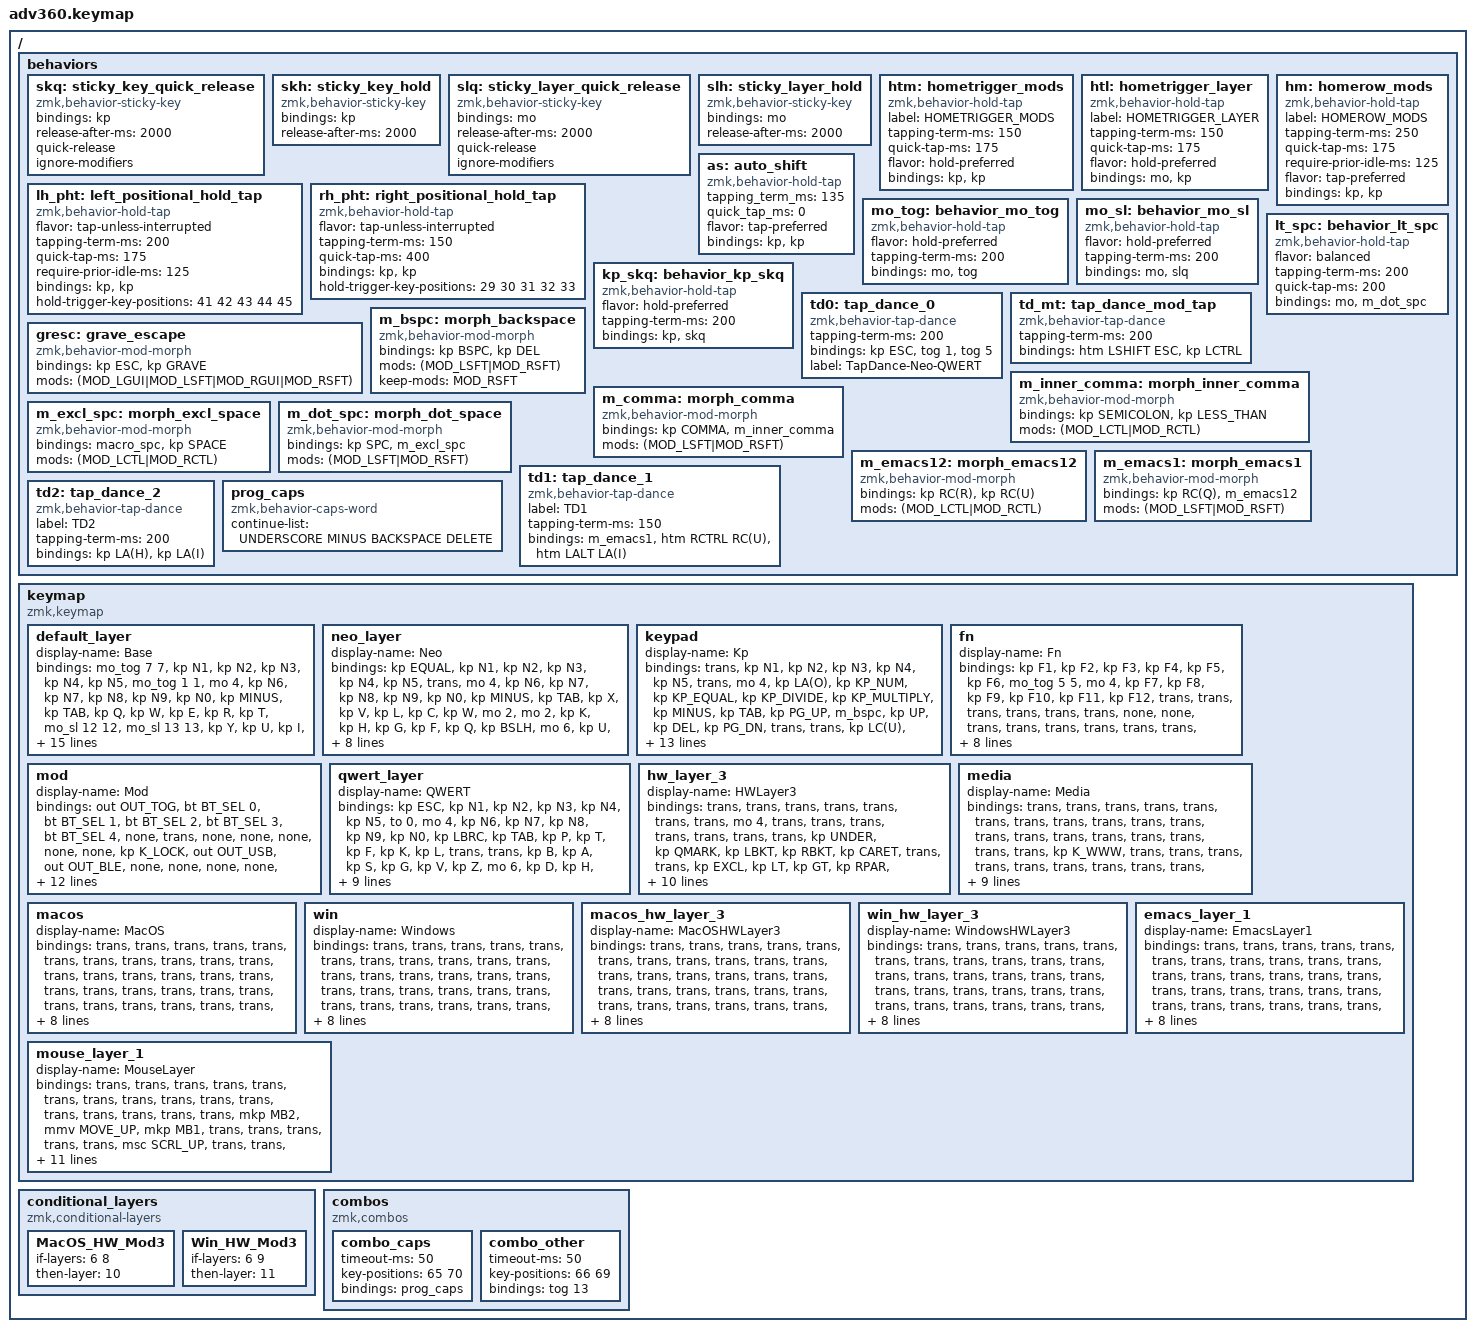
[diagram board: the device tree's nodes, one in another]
/*
 * Copyright 2025 Jonathan Pieper <jpieper@mailbox.org>
 *
 * This program is free software: you can redistribute it and/or modify
 * it under the terms of the GNU General Public License as published by
 * the Free Software Foundation, either version 3 of the License, or
 * (at your option) any later version.
 *
 * This program is distributed in the hope that it will be useful,
 * but WITHOUT ANY WARRANTY; without even the implied warranty of
 * MERCHANTABILITY or FITNESS FOR A PARTICULAR PURPOSE. See the
 * GNU General Public License for more details.
 *
 * You should have received a copy of the GNU General Public License
 * along with this program. If not, see <http://www.gnu.org/licenses/>.
 */

/*
 *
 * Neo2 layout for Kinesis Advantage 360 Pro
 *
 * The general idea is to have three layers that can be toggled:
 *
 * – standard Neo2
 * – poor man’s Neo2 ((partial) Neo2 with QWERTZ active on the host system)
 * – poor man’s QWERTZ ((partial) QWERTZ with Neo2 active on the host system)
 *
 * Inspired by:
 * - https://github.com/kaimi/tmk_keyboard/blob/neo2/keyboard/ergodox/keymap_neo.c
 * - https://github.com/urob/zmk-config/blob/main/config/base.keymap
 * - https://github.com/marlonrichert/raise-ergo
 * - https://github.com/kucera-lukas/zmk-config
 */

#include <dt-bindings/zmk/stp.h>
#include <behaviors.dtsi>
#include <dt-bindings/zmk/backlight.h>
#include <dt-bindings/zmk/bt.h>
#include <dt-bindings/zmk/keys.h>
#include <dt-bindings/zmk/outputs.h>
#include <dt-bindings/zmk/pointing.h>
#include <dt-bindings/zmk/rgb.h>

/ {
    behaviors {
        #include "macros.dtsi"
        #include "version.dtsi"

        // Sticky Keys

        skq: sticky_key_quick_release {
            compatible = "zmk,behavior-sticky-key";
            #binding-cells = <1>;
            bindings = <&kp>;
            release-after-ms = <2000>;
            quick-release;
            ignore-modifiers;
        };

        skh: sticky_key_hold {
            compatible = "zmk,behavior-sticky-key";
            #binding-cells = <1>;
            bindings = <&kp>;
            release-after-ms = <2000>;

            /delete-property/ ignore-modifiers;
        };

        //
        // Sticky Layers

        slq: sticky_layer_quick_release {
            compatible = "zmk,behavior-sticky-key";
            #binding-cells = <1>;
            bindings = <&mo>;
            release-after-ms = <2000>;
            quick-release;
            ignore-modifiers;
        };

        slh: sticky_layer_hold {
            compatible = "zmk,behavior-sticky-key";
            #binding-cells = <1>;
            bindings = <&mo>;
            release-after-ms = <2000>;

            /delete-property/ ignore-modifiers;
        };

        /*
         * Hometrigger Mods (hm): hold-preferred
         *
         * Hold (kp <1>)
         * Tap  (kp <2>)
         */

        htm: hometrigger_mods {
            compatible = "zmk,behavior-hold-tap";
            label = "HOMETRIGGER_MODS";
            #binding-cells = <2>;
            tapping-term-ms = <150>;
            quick-tap-ms = <175>;
            flavor = "hold-preferred";
            bindings = <&kp>, <&kp>;
        };

        // Hold (mo <1>)
        // Tap  (kp <2>)
        htl: hometrigger_layer {
            compatible = "zmk,behavior-hold-tap";
            label = "HOMETRIGGER_LAYER";
            #binding-cells = <2>;
            tapping-term-ms = <150>;
            quick-tap-ms = <175>;
            flavor = "hold-preferred";
            bindings = <&mo>, <&kp>;
        };


        /*
         * From https://zmk.dev/docs/keymaps/behaviors/hold-tap?examples=homerow_mods
         *
         * Homerow Mods (hm): tap-preferred
         *
         * Hold (kp <1>)
         * Tap  (kp <2>)
         */

        hm: homerow_mods {
            compatible = "zmk,behavior-hold-tap";
            label = "HOMEROW_MODS";
            #binding-cells = <2>;
            tapping-term-ms = <250>;
            quick-tap-ms = <175>;
            require-prior-idle-ms = <125>;
            flavor = "tap-preferred";
            bindings = <&kp>, <&kp>;
        };

        /*
         * cross-hand only modifiers, using tap-unless-interrupted and positional hold-tap (hold-trigger-key-positions)
         */

        lh_pht: left_positional_hold_tap {
            compatible = "zmk,behavior-hold-tap";
            #binding-cells = <2>;
            flavor = "tap-unless-interrupted";
            tapping-term-ms = <200>;   // how long a key must be pressed to trigger the "hold" behavior
            quick-tap-ms = <175>;      // press key again within quick-tap-ms to tap
            require-prior-idle-ms = <125>;
            bindings = <&kp>, <&kp>;

            // press any key not listed in hold-trigger-key-positions
            // before tapping-term-ms expires, it will produce a tap

            hold-trigger-key-positions = <41 42 43 44 45>;
        };

        rh_pht: right_positional_hold_tap {
            compatible = "zmk,behavior-hold-tap";
            #binding-cells = <2>;
            flavor = "tap-unless-interrupted";
            tapping-term-ms = <150>;
            quick-tap-ms = <400>;
            bindings = <&kp>, <&kp>;

            hold-trigger-key-positions = <29 30 31 32 33>;
        };

        /*
         * From https://zmk.dev/docs/keymaps/behaviors/hold-tap?examples=autoshift
         *
         * A popular method of implementing Autoshift in ZMK involves a C-preprocessor macro, commonly defined as AS(keycode).
         * This macro applies the LSHIFT modifier to the specified keycode when AS(keycode) is held,
         * and simply performs a keypress, &kp keycode, when the AS(keycode) binding is tapped.
         * This simplifies the use of Autoshift in a keymap, as the complete hold-tap bindings for each desired Autoshift key,
         * as in &as LS(<keycode 1>) <keycode 1> &as LS(<keycode 2>) <keycode 2> ... &as LS(<keycode n>) <keycode n>,
         * can be quite cumbersome to use when applied to a large portion of the keymap.
         *
         * See macro above:
         * #define AS(keycode) &as LS(keycode) keycode     // Autoshift Macro
         *
         * Example:
         * AS(Q) AS(W) AS(E) AS(R) AS(T) AS(Y)
         */

        as: auto_shift {
            compatible = "zmk,behavior-hold-tap";
            #binding-cells = <2>;
            tapping_term_ms = <135>;
            quick_tap_ms = <0>;
            flavor = "tap-preferred";
            bindings = <&kp>, <&kp>;
        };

        /*
         * From https://zmk.dev/docs/keymaps/behaviors/hold-tap?examples=mo_tog
         *
         * This hold-tap example implements a momentary-layer when the keybind is held and a toggle-layer when it is tapped.
         * Similar to the Autoshift and Sticky Hold use-cases, a MO_TOG(layer)
         * macro is defined such that the &mo and &tog behaviors can target a single layer.
         *
         * Hold
         *   Momentary (mo <1>)
         * Tap
         *   Toggle (tog <2>)
         */

        mo_tog: behavior_mo_tog {
            compatible = "zmk,behavior-hold-tap";
            #binding-cells = <2>;
            flavor = "hold-preferred";
            tapping-term-ms = <200>;
            bindings = <&mo>, <&tog>;
        };

        /*
         * mo_sl: Momentary Layer or Sticky Layer
         *
         * Hold
         *   Momentary (mo <1>)
         * Tap
         *   Sticky Layer (slq <2>)
         */

        mo_sl: behavior_mo_sl {
            compatible = "zmk,behavior-hold-tap";
            #binding-cells = <2>;
            flavor = "hold-preferred";
            tapping-term-ms = <200>;
            bindings = <&mo>, <&slq>;
        };

        kp_skq: behavior_kp_skq {
            compatible = "zmk,behavior-hold-tap";
            #binding-cells = <2>;
            flavor = "hold-preferred";
            tapping-term-ms = <200>;
            bindings = <&kp>, <&skq>;
        };

        // lt_spc: Momentary Layer or Space Sticky Shift Macro
        // Tap: space
        // s-   tap: dot -> space -> sticky shift
        // C-s- tap: excl(!) -> space -> sticky shift
        // Hold: Momentary new layer (mo <1>).

        lt_spc: behavior_lt_spc {
            compatible = "zmk,behavior-hold-tap";
            #binding-cells = <2>;
            flavor = "balanced";
            tapping-term-ms = <200>;
            quick-tap-ms = <200>;
            bindings = <&mo>, <&m_dot_spc>;
        };

        // Tap Dance: tap multiple times for different outcomes
        /*
         * Tap Dance 0 (td0):
         *
         * Tap 1 (kp ESC)
         * Tap 2 (mo 1) (Neo)
         * Tap 3 (mo 5) (QWERTY)
         */

        td0: tap_dance_0 {
            compatible = "zmk,behavior-tap-dance";
            #binding-cells = <0>;
            tapping-term-ms = <200>;
            bindings = <&kp ESC>, <&tog 1>, <&tog 5>;

            label = "TapDance-Neo-QWERT";
        };

        // Mod Tap (td_mt):
        //
        // Tap 1: ESC
        // Tap 2: LCTRL
        // Hold: LSHIFT

        td_mt: tap_dance_mod_tap {
            compatible = "zmk,behavior-tap-dance";
            #binding-cells = <0>;
            tapping-term-ms = <200>;
            bindings = <&htm LSHIFT ESC>, <&kp LCTRL>;
        };

        // mod-morph (Morphing Keys)
        //
        // From https://zmk.dev/docs/keymaps/behaviors/mod-morph

        gresc: grave_escape {
            compatible = "zmk,behavior-mod-morph";
            #binding-cells = <0>;
            bindings = <&kp ESC>, <&kp GRAVE>;

            mods = <(MOD_LGUI|MOD_LSFT|MOD_RGUI|MOD_RSFT)>;
        };

        // From https://github.com/urob/zmk-config/blob/main/config/base.keymap
        // Tap: backspace
        // Lshft + tap: delete
        // Rshft + tap: shift-delete.

        m_bspc: morph_backspace {
            compatible = "zmk,behavior-mod-morph";
            #binding-cells = <0>;
            bindings = <&kp BSPC>, <&kp DEL>;

            mods = <(MOD_LSFT|MOD_RSFT)>;
            keep-mods = <MOD_RSFT>;
        };

        // Tap: comma
        // Shift + tap: semicolon
        // Ctrl + shift + tap: <

        m_inner_comma: morph_inner_comma {
            compatible = "zmk,behavior-mod-morph";
            #binding-cells = <0>;
            bindings = <&kp SEMICOLON>, <&kp LESS_THAN>;

            mods = <(MOD_LCTL|MOD_RCTL)>;
        };

        m_comma: morph_comma {
            compatible = "zmk,behavior-mod-morph";
            #binding-cells = <0>;
            bindings = <&kp COMMA>, <&m_inner_comma>;

            mods = <(MOD_LSFT|MOD_RSFT)>;
        };

        // Tap: Space
        // Shift tap: dot              -> space -> sticky shift
        // C-sft-tap: Space

        m_excl_spc: morph_excl_space {
            compatible = "zmk,behavior-mod-morph";
            #binding-cells = <0>;
            bindings = <&macro_spc>, <&kp SPACE>;

            mods = <(MOD_LCTL|MOD_RCTL)>;
        };

        m_dot_spc: morph_dot_space {
            compatible = "zmk,behavior-mod-morph";
            #binding-cells = <0>;
            bindings = <&kp SPC>, <&m_excl_spc>;

            mods = <(MOD_LSFT|MOD_RSFT)>;
        };

        m_emacs12: morph_emacs12 {
            compatible = "zmk,behavior-mod-morph";
            #binding-cells = <0>;
            bindings = <&kp RC(R)>,    // C-c
	               <&kp RC(U)>;    // C-h

            mods = <(MOD_LCTL|MOD_RCTL)>;
        };

        m_emacs1: morph_emacs1 {
            compatible = "zmk,behavior-mod-morph";
            #binding-cells = <0>;
            bindings = <&kp RC(Q)>,    // C-x
	               <&m_emacs12>;

            mods = <(MOD_LSFT|MOD_RSFT)>;
        };

        td1: tap_dance_1 {
            compatible = "zmk,behavior-tap-dance";
            label = "TD1";
            #binding-cells = <0>;
            tapping-term-ms = <150>;
            bindings =
                <&m_emacs1>, // Hold:  RGUI   Tap: C-x
                <&htm RCTRL RC(U)>, // Hold: RCTL   Tap: C-h
                <&htm LALT LA(I)>; // Hold:  LALT   Tap: M-g
        };

        td2: tap_dance_2 {
            compatible = "zmk,behavior-tap-dance";
            label = "TD2";
            #binding-cells = <0>;
            tapping-term-ms = <200>;
            bindings =
                <&kp LA(H)>, // M-s
                <&kp LA(I)>; // M-g
        };

    	prog_caps: prog_caps {
            compatible = "zmk,behavior-caps-word";
            #binding-cells = <0>;
            continue-list = <UNDERSCORE MINUS BACKSPACE DELETE>;
        };

    };

    keymap {
        compatible = "zmk,keymap";

        /* Keymap 0:
     *
     * Default Layer (Neo2, original QWERTY)
     *
     * This is mostly just the standard Layout with some modifications.
     *
     * ,--------------------------------------------------.           ,--------------------------------------------------.
     * |  Esc   |   1  |   2  |   3  |   4  |   5  |Neo/Md|           | To 4 |   6  |   7  |   8  |   9  |   0  |   -    |
     * |--------+------+------+------+------+-------------|           |------+------+------+------+------+------+--------|
     * |  Tab   |   X  |   V  |   L  |   C  |   W  | C-c  |           | C-x  |   K  |   H  |   G  |   F  |   Q  |   ß  \ |
     * |--------+------+------+------+------+------|------|           |------|------+------+------+------+------+--------|
     * |  M-w   |   U  |   I  |   A  |   E  |   O  | M-s  |           | M-x  |   S  |   N  |   R  |   T  |   D  |   Y    |
     * |  CAPS  | LGUI | LSHFT| LALT | LCTRL|      |      |           |      |      | RCTRL| RALT | RSHFT| RGUI | CAPS   | <-- Homerow Mods
     * |--------+------+------+------+------+------|------'           `------|------+------+------+------+------+--------|
     * |  LSft  |   Ü  |   Ö  |   Ä  |   P  |   Z  |                         |   B  |   M  |   ,  |   .  |   J  |  RSft  |
     * |--------+------+------+------+------+------'                         `------+------+------+------+------+--------|
     * |  Fn    | ESC  | Kp   | LEFT | RIGHT|                                       |  UP  | DOWN |   [  |   ]  | Fn     |
     * `------------------------------------'                                       `------------------------------------'
     *                                        ,-------------.       ,-------------.
     *                                        | CTRL | ALT  |       | LGUI | CTRL |
     *                                 ,------|------|------|       |------+------+------.
     *                                 |      |      | Mod3 |       | Mod3 |      |      |
     *                                 | SHIFT| SPC  |------|       |------| RET  | SHIFT|
     *                                 |      |      | Mod4 |       | Mod4 |      |      |
     *                                 `--------------------'       `--------------------'
     */

        default_layer {
            display-name = "Base";
            bindings = <
&mo_tog 7 7      &kp N1          &kp N2            &kp N3          &kp N4           &kp N5          &mo_tog 1 1                                                          &mo 4                 &kp N6          &kp N7           &kp N8          &kp N9            &kp N0             &kp MINUS
&kp TAB          &kp Q           &kp W             &kp E           &kp R            &kp T           &mo_sl 12 12                                                         &mo_sl 13 13          &kp Y           &kp U            &kp I           &kp O             &kp P              &kp LBKT
&kp CAPS         &hm LGUI A    &hm LALT S        &hm LSHFT D     &hm LCTRL F      &hm RALT G      &htm CAPS LC(H)   &kp LCTRL     &kp LALT      &kp LGUI       &kp RCTRL  &htm CAPS LA(Q)    &hm RALT H      &hm RCTRL J      &hm RSHIFT K    &hm LALT L        &hm RGUI SEMI      &hm CAPS SQT
&kp LSHFT  &kp Z       &kp X             &kp C           &kp V            &kp B                                           &kp_skq CAPS CAPS  &kp_skq BSLH BSLH                       &kp N           &kp M            &m_comma        &kp DOT           &kp FSLH           &kp RSHFT
&mo_sl 2 3       &m_dot_spc      &mo_tog 2 2       &htm CAPS LEFT   &htm LGUI RIGHT                   &kp BSPC  &key_repeat   &mo_tog 2 2   &kp RIGHT_ALT  &kp ENTER  &kp SPACE            &htm CAPS UP     &htm RALT DOWN  &htm CAPS LBKT    &htm RALT RBKT     &mo_sl 12 3
            >;
        };

        /* Keymap 1:
     *
     * Hardware Neo2
     *
     * This is a hardware implementation of Neo2. Allowing to type in Neo2 even if it is not installed.
     *
     * ,--------------------------------------------------.           ,--------------------------------------------------.
     * |  Esc   |   1  |   2  |   3  |   4  |   5  | trans|           | To 4 |   6  |   7  |   8  |   9  |   0  |   -    |
     * |--------+------+------+------+------+-------------|           |------+------+------+------+------+------+--------|
     * |  Tab   |   X  |   V  |   L  |   C  |   W  | C-c  |           | C-x  |   K  |   H  |   G  |   F  |   Q  |   ß    |
     * |--------+------+------+------+------+------|------|           |------|------+------+------+------+------+--------|
     * | HMod3  |   U  |   I  |   A  |   E  |   O  | M-s  |           | M-x  |   S  |   N  |   R  |   T  |   D  |   Y    |
     * |--------+------+------+------+------+------|------'           `------|------+------+------+------+------+--------|
     * |  LSft  |  Ü [ |  Ö / |  Ä ; |   P  |   Z  |                         |   B  |   M  |   ,  |   .  |   J  |  RSft  |
     * |--------+------+------+------+------+------'                         `------+------+------+------+------+--------|
     * |  Fn    | ESC  | LGUI | LEFT | RIGHT|                                       |  UP  | DOWN |   [  |   ]  | Fn     |
     * `------------------------------------'                                       `------------------------------------'
     *                                        ,-------------.       ,-------------.
     *                                        | trans| trans|       | trans| trans|
     *                                 ,------|------|------|       |------+------+------.
     *                                 |      |      | trans|       | Mod3 |      |      |
     *                                 | trans| trans|------|       |------| trans| trans|
     *                                 |      |      | trans|       | Mod4 |      |      |
     *                                 `--------------------'       `--------------------'
     */

        neo_layer {
            display-name = "Neo";
            bindings = <
&kp EQUAL    &kp N1    &kp N2      &kp N3    &kp N4     &kp N5  &trans                                      &mo 4   &kp N6  &kp N7  &kp N8     &kp N9    &kp N0    &kp MINUS
&kp TAB      &kp X     &kp V       &kp L     &kp C      &kp W   &mo 2                                       &mo 2   &kp K   &kp H   &kp G      &kp F     &kp Q     &kp BSLH
&mo 6        &kp U     &kp I       &kp A     &kp E      &kp O   &mo 6   &trans  &trans      &trans  &trans  &mo 6   &kp S   &kp N   &kp R      &kp T     &kp D     &kp Z
&kp LSHFT    &kp LBKT  &kp SLASH   &kp SEMI  &kp P      &kp Y                   &mo 6       &mo 6                   &kp B   &kp M   &kp COMMA  &kp DOT   &kp J     &kp RSHFT
&mo_sl 2 3   &kp ESC   &mo_sl 2 2  &kp LEFT  &kp RIGHT          &trans  &trans  &mo 2       &mo 2   &trans  &trans          &kp UP  &kp DOWN   &kp LBKT  &kp RBKT  &trans
            >;
        };

        /* Keymap 2:
     *
     * Keypad (Kp, Mod4)
     *
     * This is a hardware implementation of the Neo2-Mod4 Keypad Layer.
     *
     * ,--------------------------------------------------.           ,--------------------------------------------------.
     * |  Esc   | trans| trans| trans| trans| trans| trans|           | To 4 | M-f  |  NUM |   =  |   /  |   *  |   -    |
     * |--------+------+------+------+------+-------------|           |------+------+------+------+------+------+--------|
     * |  Tab   | Pg_Up| BKSP |  UP  |  DEL | Pg_Dn| trans|           | trans| C-h  |   7  |   8  |   9  |   -  |   \    |
     * |--------+------+------+------+------+------|------|           |------|------+------+------+------+------+--------|
     * |  Mod3  | HOME | LEFT | DOWN | RIGHT| END  | trans|           | trans| M-s  |   4  |   5  |   6  |   +  |   '    |
     * |--------+------+------+------+------+------|------'           `------|------+------+------+------+------+--------|
     * |  LSft  | ESC  |  TAB | INS  | RET  | UNDO |                         |   :  |   1  |   2  |   3  |  RET |  RSft  |
     * |--------+------+------+------+------+------'                         `------+------+------+------+------+--------|
     * |  MacOST|HMod3 | trans| BriDn| BriUp|                                       | VolUp| VolDn| MUTE | PLAY | Fn     |
     * `------------------------------------'                                       `------------------------------------'
     *                                        ,-------------.       ,-------------.
     *                                        | trans| trans|       | trans| trans|
     *                                 ,------|------|------|       |------+------+------.
     *                                 |      |      | trans|       | trans|      |      |
     *                                 | trans| trans|------|       |------| DEL  |  0   |
     *                                 |      |      | trans|       | trans|      |      |
     *                                 `--------------------'       `--------------------'
     */

        keypad {
            display-name = "Kp";
            bindings = <
&trans       &kp N1     &kp N2    &kp N3        &kp N4        &kp N5      &trans                                       &mo 4         &kp LA(O)  &kp KP_NUM    &kp KP_EQUAL  &kp KP_DIVIDE  &kp KP_MULTIPLY   &kp MINUS
&kp TAB      &kp PG_UP  &m_bspc   &kp UP        &kp DEL       &kp PG_DN   &trans                                       &trans        &kp LC(U)  &kp KP_N7     &kp KP_N8     &kp KP_N9      &kp KP_MINUS      &kp BSLH
&kp CAPS     &kp HOME   &kp LEFT  &kp DOWN      &kp RIGHT     &kp END     &trans  &trans  &trans      &trans  &trans   &trans        &kp LA(H)  &kp KP_N4     &kp KP_N5     &kp KP_N6      &kp KP_PLUS       &kp SQT
&trans       &kp ESC    &kp TAB   &kp LG(V)     &kp RET       &kp K_UNDO                  &trans      &trans                         &kp COLON  &kp KP_N1     &kp KP_N2     &kp KP_N3      &kp KP_ENTER      &kp RSHFT
&mo_tog 7 5  &mo 6      &trans    &kp C_BRI_DN  &kp C_BRI_UP              &trans  &trans  &trans      &trans  &kp DEL  &kp NUMBER_0             &kp C_VOL_UP  &kp C_VOL_DN  &kp C_MUTE     &kp K_PLAY_PAUSE  &trans
            >;
        };

        /* Keymap 3:
     *
     * Function Keys (Fn)
     *
     * This is the function layer (Fn).
     *
     * ,--------------------------------------------------.           ,--------------------------------------------------.
     * |  F1    | F2   | F3   | F4   | F5   | F6   | QWERT|           | Mo 4 | F7   |  F8  |  F9  | F10  | F11  | F12    |
     * |--------+------+------+------+------+-------------|           |------+------+------+------+------+------+--------|
     * |  trans | trans| trans| trans| trans| trans| trans|           | trans| trans| trans| trans| trans| trans| trans  |
     * |--------+------+------+------+------+------|------|           |------|------+------+------+------+------+--------|
     * |  trans | trans| trans| trans| trans| trans| trans|           | trans| trans| trans| trans| trans| trans| trans  |
     * |--------+------+------+------+------+------|------'           `------|------+------+------+------+------+--------|
     * |  trans | trans| trans| trans| trans| trans|                         | trans| trans| trans| trans| trans| trans  |
     * |--------+------+------+------+------+------'                         `------+------+------+------+------+--------|
     * |  trans | trans| trans| trans| trans|                                       | trans| trans| trans| trans| trans  |
     * `------------------------------------'                                       `------------------------------------'
     *                                        ,-------------.       ,-------------.
     *                                        | trans| trans|       | trans| trans|
     *                                 ,------|------|------|       |------+------+------.
     *                                 |      |      | trans|       | trans|      |      |
     *                                 | trans| trans|------|       |------| trans| trans|
     *                                 |      |      | trans|       | trans|      |      |
     *                                 `--------------------'       `--------------------'
     */

        fn {
            display-name = "Fn";
            bindings = <
&kp F1  &kp F2  &kp F3  &kp F4  &kp F5  &kp F6  &mo_tog 5 5                                         &mo 4   &kp F7  &kp F8  &kp F9  &kp F10  &kp F11  &kp F12
&trans  &trans  &trans  &trans  &trans  &trans  &none                                               &none   &trans  &trans  &trans  &trans   &trans   &trans
&trans  &trans  &trans  &trans  &trans  &trans  &none        &trans  &trans      &kp K_APP  &trans  &none   &trans  &trans  &trans  &trans   &trans   &trans
&trans  &trans  &trans  &trans  &trans  &trans                       &trans      &trans                     &trans  &trans  &trans  &trans   &trans   &trans
&trans  &trans  &trans  &trans  &trans          &kp SPACE    &trans  &trans      &trans     &trans  &trans          &trans  &trans  &trans   &trans   &trans
            >;
        };

        /* Keymap 4:
     *
     * Keyboard Modification Layer (Mod)
     *
     * This is the Mod Layer.
     *
     * ,--------------------------------------------------.           ,--------------------------------------------------.
     * |  trans | trans| trans| trans| trans| trans| trans|           | trans| trans| trans| trans| trans| trans| trans  |
     * |--------+------+------+------+------+-------------|           |------+------+------+------+------+------+--------|
     * |  trans | trans| trans| trans| trans| trans| trans|           | trans| trans| trans| trans| trans| trans| trans  |
     * |--------+------+------+------+------+------|------|           |------|------+------+------+------+------+--------|
     * |  trans | trans| trans| trans| trans| trans| trans|           | trans| trans| trans| trans| trans| trans| trans  |
     * |--------+------+------+------+------+------|------'           `------|------+------+------+------+------+--------|
     * |  trans | trans| trans| trans| trans| trans|                         | trans| trans| trans| trans| trans| trans  |
     * |--------+------+------+------+------+------'                         `------+------+------+------+------+--------|
     * |  trans | trans| trans| trans| trans|                                       | trans| trans| trans| trans| trans  |
     * `------------------------------------'                                       `------------------------------------'
     *                                        ,-------------.       ,-------------.
     *                                        | trans| trans|       | trans| trans|
     *                                 ,------|------|------|       |------+------+------.
     *                                 |      |      | trans|       | trans|      |      |
     *                                 | trans| trans|------|       |------| trans| trans|
     *                                 |      |      | trans|       | trans|      |      |
     *                                 `--------------------'       `--------------------'
     */

        mod {
            display-name = "Mod";
            bindings = <
&out OUT_TOG    &bt BT_SEL 0  &bt BT_SEL 1  &bt BT_SEL 2  &bt BT_SEL 3  &bt BT_SEL 4  &none                                                                     &trans           &none  &none       &none       &none  &none  &kp K_LOCK
&out OUT_USB    &out OUT_BLE  &none         &none         &none         &none         &bootloader                                                               &bootloader      &none  &none       &none       &none  &none  &none
&studio_unlock  &none         &none         &none         &none         &none         &none            &bt BT_PRV       &bt BT_NXT      &bt BT_CLR  &none       &stp STP_BAT     &none  &none       &none       &none  &none  &none
&none           &none         &none         &none         &macro_ver    &none                                           &rgb_ug RGB_BRI  &rgb_ug RGB_HUI                         &none  &none       &none       &none  &none  &none
&none           &none         &none         &none         &none                       &soft_off        &rgb_ug RGB_TOG  &rgb_ug RGB_BRD  &rgb_ug RGB_HUI  &bl BL_TOG  &rgb_ug RGB_TOG   &bl BL_INC  &bl BL_DEC  &bl BL_CYCLE  &none  &none
            >;
        };

        /* Keymap 5:
     *
     * QWERTY Layer (QWERT)
     *
     * This is the poor mans QWERTY. Sometimes you need to enter in qwerty even if neo is active.
     *
     * ,--------------------------------------------------.           ,--------------------------------------------------.
     * |  Esc   |   1  |   2  |   3  |   4  |   5  | To 0 |           | To 4 |   6  |   7  |   8  |   9  |   0  |   -    |
     * |--------+------+------+------+------+-------------|           |------+------+------+------+------+------+--------|
     * |  Tab   |   Q  |   W  |   E  |   R  |   T  | trans|           | trans|   Z  |   U  |   I  |   O  |   P  |  Ü [   |
     * |--------+------+------+------+------+------|------|           |------|------+------+------+------+------+--------|
     * | HMod3  |   A  |   S  |   D  |   F  |   G  | trans|           | trans|   H  |   J  |   K  |   L  |  Ö : |  Ä ;   |
     * |--------+------+------+------+------+------|------'           `------|------+------+------+------+------+--------|
     * |  LSft  |   Y  |   X  |   C  |   V  |   B  |                         |   N  |   M  |   ,  |   .  |   /  |  RSft  |
     * |--------+------+------+------+------+------'                         `------+------+------+------+------+--------|
     * |  Mo 0  | trans| LGUI | LEFT | RIGHT|                                       |  UP  | DOWN |   [  |   ]  | Fn     |
     * `------------------------------------'                                       `------------------------------------'
     *                                        ,-------------.       ,-------------.
     *                                        | LCTL | LALT |       | LGUI | RCTL |
     *                                 ,------|------|------|       |------+------+------.
     *                                 |      |      | CAPS |       | \    |      |      |
     *                                 | BSPC | DEL  |------|       |------| RET  | Space|
     *                                 |      |      |HMod4 |       | RALT |      |      |
     *                                 `--------------------'       `--------------------'
     */

        qwert_layer {
            display-name = "QWERT";
            bindings = <
&kp ESC    &kp N1   &kp N2    &kp N3    &kp N4     &kp N5  &to 0                                                       &mo 4        &kp N6  &kp N7     &kp N8     &kp N9    &kp N0     &kp LBRC
&kp TAB    &kp P    &kp T     &kp F     &kp K      &kp L   &trans                                                      &trans       &kp B   &kp A      &kp S      &kp G     &kp V      &kp Z
&mo 6      &kp D    &kp H     &kp SEMI  &kp O      &kp I   &trans   &kp LCTRL  &kp LALT      &kp LGUI       &kp RCTRL  &trans       &kp U   &kp SLASH  &kp Y      &kp E     &kp X      &kp C
&kp LSHFT  &kp SQT  &kp Q     &kp R     &kp W      &kp N                       &kp CAPS      &kp BACKSLASH                          &kp J   &kp M      &kp COMMA  &kp DOT   &kp MINUS  &kp RSHFT
&mo 0      &trans   &kp LGUI  &kp LEFT  &kp RIGHT          &m_bspc  &kp DEL    &mo 2         &kp RIGHT_ALT  &kp ENTER  &lt_spc 2 0          &kp UP     &kp DOWN   &kp LBKT  &kp RBKT   &mo 0
            >;
        };

        /* Keymap 6:
     *
     * Hardware Neo2 Layer 3 (HMod3)
     *
     * This is the hardware implementation of the Neo2 Mod3 Layer (Special Characters).
     *
     * ,--------------------------------------------------.           ,--------------------------------------------------.
     * |  trans | trans| trans| trans| trans| trans| trans|           | trans| trans| trans| trans| trans| trans| trans  |
     * |--------+------+------+------+------+-------------|           |------+------+------+------+------+------+--------|
     * |  trans | trans| trans| trans| trans| trans| trans|           | trans| trans| trans| trans| trans| trans| trans  |
     * |--------+------+------+------+------+------|------|           |------|------+------+------+------+------+--------|
     * |  trans | trans| trans| trans| trans| trans| trans|           | trans| trans| trans| trans| trans| trans| trans  |
     * |--------+------+------+------+------+------|------'           `------|------+------+------+------+------+--------|
     * |  trans | trans| trans| trans| trans| trans|                         | trans| trans| trans| trans| trans| trans  |
     * |--------+------+------+------+------+------'                         `------+------+------+------+------+--------|
     * |  trans | trans| trans| trans| trans|                                       | trans| trans| trans| trans| trans  |
     * `------------------------------------'                                       `------------------------------------'
     *                                        ,-------------.       ,-------------.
     *                                        | trans| trans|       | trans| trans|
     *                                 ,------|------|------|       |------+------+------.
     *                                 |      |      | trans|       | trans|      |      |
     *                                 | trans| trans|------|       |------| trans| trans|
     *                                 |      |      | trans|       | trans|      |      |
     *                                 `--------------------'       `--------------------'
     */

        hw_layer_3 {
            display-name = "HWLayer3";
            bindings = <
&trans  &trans     &trans     &trans    &trans     &trans     &trans                                      &mo 4   &trans     &trans     &trans    &trans     &trans     &trans
&trans  &kp UNDER  &kp QMARK  &kp LBKT  &kp RBKT   &kp CARET  &trans                                      &trans  &kp EXCL   &kp LT     &kp GT    &kp RPAR   &kp CARET  &trans
&trans  &kp BSLH   &kp AMPS   &kp STAR  &kp LPAR   &kp RBRC   &trans  &none   &none       &trans  &none   &trans  &kp UNDER  &kp LPAR   &kp RPAR  &kp FSLH   &kp GT     &kp AT
&trans  &kp BSLH   &kp DLLR   &kp PIPE  &kp TILDE  &kp GRAVE                  &none       &none                   &kp RBKT   &kp PRCNT  &kp AT    &kp SQT    &kp LT     &trans
&trans  &trans     &trans     &trans    &trans                &trans  &trans  &trans      &trans  &trans  &trans             &trans     &trans    &trans     &trans     &trans
            >;
        };

        /* Keymap 7:
     *
     * Media Keys (Media)
     *
     * This is the hardware implementation of the Neo2 Mod3 Layer (Special Characters).
     *
     * ,--------------------------------------------------.           ,--------------------------------------------------.
     * |  trans | trans| trans| trans| trans| trans| trans|           | trans| trans| trans| trans| trans| trans| trans  |
     * |--------+------+------+------+------+-------------|           |------+------+------+------+------+------+--------|
     * |  trans | trans| trans| trans| trans| trans| trans|           | trans| trans| trans| trans| trans| trans| trans  |
     * |--------+------+------+------+------+------|------|           |------|------+------+------+------+------+--------|
     * |  trans | trans| trans| trans| trans| trans| trans|           | trans| trans| trans| trans| trans| trans| trans  |
     * |--------+------+------+------+------+------|------'           `------|------+------+------+------+------+--------|
     * |  trans | trans| trans| trans| trans| trans|                         | trans| trans| trans| trans| trans| trans  |
     * |--------+------+------+------+------+------'                         `------+------+------+------+------+--------|
     * |  trans | trans| trans| trans| trans|                                       | trans| trans| trans| trans| trans  |
     * `------------------------------------'                                       `------------------------------------'
     *                                        ,-------------.       ,-------------.
     *                                        | trans| trans|       | trans| trans|
     *                                 ,------|------|------|       |------+------+------.
     *                                 |      |      | trans|       | trans|      |      |
     *                                 | trans| trans|------|       |------| trans| trans|
     *                                 |      |      | trans|       | trans|      |      |
     *                                 `--------------------'       `--------------------'
     */

        media {
            display-name = "Media";
            bindings = <
&trans  &trans  &trans  &trans  &trans  &trans     &trans                                      &trans  &trans  &trans  &trans  &trans  &trans  &trans
&trans  &trans  &trans  &trans  &trans  &kp K_WWW  &trans                                      &trans  &trans  &trans  &trans  &trans  &trans  &trans
&trans  &trans  &trans  &trans  &trans  &trans     &trans  &trans  &trans      &trans  &trans  &trans  &trans  &trans  &trans  &trans  &trans  &trans
&trans  &trans  &trans  &trans  &trans  &trans                     &trans      &trans                  &trans  &trans  &trans  &trans  &trans  &trans
&trans  &trans  &trans  &trans  &trans             &trans  &trans  &trans      &trans  &trans  &trans          &trans  &trans  &macro_braces  &macro_quotes  &trans
            >;
        };

        /* Keymap 8:
     *
     * Apple MacOS Modifications (MacOS)
     *
     * This is the hardware implementation of the Neo2 Mod3 Layer (Special Characters).
     *
     * ,--------------------------------------------------.           ,--------------------------------------------------.
     * |  trans | trans| trans| trans| trans| trans| trans|           | trans| trans| trans| trans| trans| trans| trans  |
     * |--------+------+------+------+------+-------------|           |------+------+------+------+------+------+--------|
     * |  trans | trans| trans| trans| trans| trans| trans|           | trans| trans| trans| trans| trans| trans| trans  |
     * |--------+------+------+------+------+------|------|           |------|------+------+------+------+------+--------|
     * |  trans | trans| trans| trans| trans| trans| trans|           | trans| trans| trans| trans| trans| trans| trans  |
     * |--------+------+------+------+------+------|------'           `------|------+------+------+------+------+--------|
     * |  trans | trans| trans| trans| trans| trans|                         | trans| trans| trans| trans| trans| trans  |
     * |--------+------+------+------+------+------'                         `------+------+------+------+------+--------|
     * |  trans | trans| trans| trans| trans|                                       | trans| trans| trans| trans| trans  |
     * `------------------------------------'                                       `------------------------------------'
     *                                        ,-------------.       ,-------------.
     *                                        | trans| trans|       | trans| trans|
     *                                 ,------|------|------|       |------+------+------.
     *                                 |      |      | trans|       | trans|      |      |
     *                                 | trans| trans|------|       |------| trans| trans|
     *                                 |      |      | trans|       | trans|      |      |
     *                                 `--------------------'       `--------------------'
     */

        macos {
            display-name = "MacOS";
            bindings = <
&trans  &trans  &trans  &trans  &trans     &trans  &trans                                        &trans  &trans  &trans  &trans  &trans  &trans  &trans
&trans  &trans  &trans  &trans  &trans     &trans  &trans                                        &trans  &trans  &trans  &trans  &trans  &trans  &trans
&trans  &trans  &trans  &trans  &trans     &trans  &trans  &kp LCMD  &trans      &trans  &trans  &trans  &trans  &trans  &trans  &trans  &trans  &trans
&trans  &trans  &trans  &trans  &trans     &trans                    &trans      &trans                  &trans  &trans  &trans  &trans  &trans  &trans
&trans  &trans  &trans  &trans  &kp LCTRL          &trans  &trans    &trans      &trans  &trans  &trans          &trans  &trans  &trans  &trans  &trans
            >;
        };

        /* Keymap 9:
     *
     * Windows Modifications (Win)
     *
     * This is the hardware implementation of the Neo2 Mod3 Layer (Special Characters).
     *
     * ,--------------------------------------------------.           ,--------------------------------------------------.
     * |  trans | trans| trans| trans| trans| trans| trans|           | trans| trans| trans| trans| trans| trans| trans  |
     * |--------+------+------+------+------+-------------|           |------+------+------+------+------+------+--------|
     * |  trans | trans| trans| trans| trans| trans| trans|           | trans| trans| trans| trans| trans| trans| trans  |
     * |--------+------+------+------+------+------|------|           |------|------+------+------+------+------+--------|
     * |  trans | trans| trans| trans| trans| trans| trans|           | trans| trans| trans| trans| trans| trans| trans  |
     * |--------+------+------+------+------+------|------'           `------|------+------+------+------+------+--------|
     * |  trans | trans| trans| trans| trans| trans|                         | trans| trans| trans| trans| trans| trans  |
     * |--------+------+------+------+------+------'                         `------+------+------+------+------+--------|
     * |  trans | trans| trans| trans| trans|                                       | trans| trans| trans| trans| trans  |
     * `------------------------------------'                                       `------------------------------------'
     *                                        ,-------------.       ,-------------.
     *                                        | trans| trans|       | trans| trans|
     *                                 ,------|------|------|       |------+------+------.
     *                                 |      |      | trans|       | trans|      |      |
     *                                 | trans| trans|------|       |------| trans| trans|
     *                                 |      |      | trans|       | trans|      |      |
     *                                 `--------------------'       `--------------------'
     */

        win {
            display-name = "Windows";
            bindings = <
&trans  &trans  &trans  &trans  &trans  &trans  &trans                                      &trans  &trans  &trans  &trans  &trans  &trans  &trans
&trans  &trans  &trans  &trans  &trans  &trans  &trans                                      &trans  &trans  &trans  &trans  &trans  &trans  &trans
&trans  &trans  &trans  &trans  &trans  &trans  &trans  &trans  &trans      &trans  &trans  &trans  &trans  &trans  &trans  &trans  &trans  &trans
&trans  &trans  &trans  &trans  &trans  &trans                  &trans      &trans                  &trans  &trans  &trans  &trans  &trans  &trans
&trans  &trans  &trans  &trans  &trans          &trans  &trans  &trans      &trans  &trans  &trans          &trans  &trans  &trans  &trans  &trans
            >;
        };

        /* Keymap 10:
     *
     * MacOS Modifications for Hardware Neo2 Layer 3 (MacOSHMod3)
     *
     * This is the hardware implementation of the Neo2 Mod3 Layer on MacOS (Special Characters).
     *
     * ,--------------------------------------------------.           ,--------------------------------------------------.
     * |  trans | trans| trans| trans| trans| trans| trans|           | trans| trans| trans| trans| trans| trans| trans  |
     * |--------+------+------+------+------+-------------|           |------+------+------+------+------+------+--------|
     * |  trans | trans| trans| trans| trans| trans| trans|           | trans| trans| trans| trans| trans| trans| trans  |
     * |--------+------+------+------+------+------|------|           |------|------+------+------+------+------+--------|
     * |  trans | trans| trans| trans| trans| trans| trans|           | trans| trans| trans| trans| trans| trans| trans  |
     * |--------+------+------+------+------+------|------'           `------|------+------+------+------+------+--------|
     * |  trans | trans| trans| trans| trans| trans|                         | trans| trans| trans| trans| trans| trans  |
     * |--------+------+------+------+------+------'                         `------+------+------+------+------+--------|
     * |  trans | trans| trans| trans| trans|                                       | trans| trans| trans| trans| trans  |
     * `------------------------------------'                                       `------------------------------------'
     *                                        ,-------------.       ,-------------.
     *                                        | trans| trans|       | trans| trans|
     *                                 ,------|------|------|       |------+------+------.
     *                                 |      |      | trans|       | trans|      |      |
     *                                 | trans| trans|------|       |------| trans| trans|
     *                                 |      |      | trans|       | trans|      |      |
     *                                 `--------------------'       `--------------------'
     */

        macos_hw_layer_3 {
            display-name = "MacOSHWLayer3";
            bindings = <
&trans  &trans  &trans  &trans  &trans  &trans  &trans                                      &trans  &trans  &trans  &trans  &trans  &trans  &trans
&trans  &trans  &trans  &trans  &trans  &trans  &trans                                      &trans  &trans  &trans  &trans  &trans  &trans  &trans
&trans  &trans  &trans  &trans  &trans  &trans  &trans  &trans  &trans      &trans  &trans  &trans  &trans  &trans  &trans  &trans  &trans  &trans
&trans  &trans  &trans  &trans  &trans  &trans                  &trans      &trans                  &trans  &trans  &trans  &trans  &trans  &trans
&trans  &trans  &trans  &trans  &trans          &trans  &trans  &trans      &trans  &trans  &trans          &trans  &trans  &trans  &trans  &trans
            >;
        };

        /* Keymap 11:
     *
     * Windows Modifications for Hardware Neo2 Layer 3 (WindowsHMod3)
     *
     * This is the hardware implementation of the Neo2 Mod3 Layer on Windows (Special Characters).
     *
     * ,--------------------------------------------------.           ,--------------------------------------------------.
     * |  trans | trans| trans| trans| trans| trans| trans|           | trans| trans| trans| trans| trans| trans| trans  |
     * |--------+------+------+------+------+-------------|           |------+------+------+------+------+------+--------|
     * |  trans | trans| trans| trans| trans| trans| trans|           | trans| trans| trans| trans| trans| trans| trans  |
     * |--------+------+------+------+------+------|------|           |------|------+------+------+------+------+--------|
     * |  trans | trans| trans| trans| trans| trans| trans|           | trans| trans| trans| trans| trans| trans| trans  |
     * |--------+------+------+------+------+------|------'           `------|------+------+------+------+------+--------|
     * |  trans | trans| trans| trans| trans| trans|                         | trans| trans| trans| trans| trans| trans  |
     * |--------+------+------+------+------+------'                         `------+------+------+------+------+--------|
     * |  trans | trans| trans| trans| trans|                                       | trans| trans| trans| trans| trans  |
     * `------------------------------------'                                       `------------------------------------'
     *                                        ,-------------.       ,-------------.
     *                                        | trans| trans|       | trans| trans|
     *                                 ,------|------|------|       |------+------+------.
     *                                 |      |      | trans|       | trans|      |      |
     *                                 | trans| trans|------|       |------| trans| trans|
     *                                 |      |      | trans|       | trans|      |      |
     *                                 `--------------------'       `--------------------'
     */

        win_hw_layer_3 {
            display-name = "WindowsHWLayer3";
            bindings = <
&trans  &trans  &trans  &trans  &trans  &trans  &trans                                      &trans  &trans  &trans  &trans  &trans  &trans  &trans
&trans  &trans  &trans  &trans  &trans  &trans  &trans                                      &trans  &trans  &trans  &trans  &trans  &trans  &trans
&trans  &trans  &trans  &trans  &trans  &trans  &trans  &trans  &trans      &trans  &trans  &trans  &trans  &trans  &trans  &trans  &trans  &trans
&trans  &trans  &trans  &trans  &trans  &trans                  &trans      &trans                  &trans  &trans  &trans  &trans  &trans  &trans
&trans  &trans  &trans  &trans  &trans          &trans  &trans  &trans      &trans  &trans  &trans          &trans  &trans  &trans  &trans  &trans
            >;
        };

        /* Keymap 12:
     *
     * Emacs Modifications (EmacsLayer1)
     *
     * These are some keybindings and macros for easier Emacs usage on vanilla keybindings.
     *
     * ,--------------------------------------------------.           ,--------------------------------------------------.
     * |  trans | trans| trans| trans| trans| trans| trans|           | trans| trans| trans| trans| trans| trans| trans  |
     * |--------+------+------+------+------+-------------|           |------+------+------+------+------+------+--------|
     * |  trans | trans| trans| trans| trans| trans| trans|           | trans| trans| trans| trans| trans| trans| trans  |
     * |--------+------+------+------+------+------|------|           |------|------+------+------+------+------+--------|
     * |  trans | trans| trans| trans| trans| trans| trans|           | trans| trans| trans| trans| trans| trans| trans  |
     * |--------+------+------+------+------+------|------'           `------|------+------+------+------+------+--------|
     * |  trans | trans| trans| trans| trans| trans|                         | trans| trans| trans| trans| trans| trans  |
     * |--------+------+------+------+------+------'                         `------+------+------+------+------+--------|
     * |  trans | trans| trans| trans| trans|                                       | trans| trans| trans| trans| trans  |
     * `------------------------------------'                                       `------------------------------------'
     *                                        ,-------------.       ,-------------.
     *                                        | trans| trans|       | trans| trans|
     *                                 ,------|------|------|       |------+------+------.
     *                                 |      |      | trans|       | trans|      |      |
     *                                 | trans| trans|------|       |------| trans| trans|
     *                                 |      |      | trans|       | trans|      |      |
     *                                 `--------------------'       `--------------------'
     */

        emacs_layer_1 {
            display-name = "EmacsLayer1";
            bindings = <
&trans  &trans  &trans  &trans  &trans  &trans  &trans                                            &trans  &trans  &trans  &trans  &trans  &trans  &trans
&trans  &trans  &trans  &trans  &trans  &trans  &trans                                            &trans  &trans  &trans  &trans  &trans  &trans  &trans
&trans  &trans  &trans  &trans  &trans  &trans  &trans  &kp RC(Q)  &trans      &trans  &kp LC(R)  &trans  &trans  &trans  &trans  &trans  &trans  &trans
&trans  &trans  &trans  &trans  &trans  &trans                     &trans      &trans                     &trans  &trans  &trans  &trans  &trans  &trans
&trans  &trans  &trans  &trans  &trans          &trans  &trans     &trans      &trans  &trans     &trans          &trans  &trans  &trans  &trans  &trans
            >;
        };

        mouse_layer_1 {
            display-name = "MouseLayer";
            bindings = <
&trans  &trans  &trans          &trans          &trans           &trans  &trans                                                &trans    &trans  &trans          &trans          &trans           &trans  &trans
&trans  &trans  &mkp MB2  &mmv MOVE_UP    &mkp MB1           &trans  &trans                                                &trans    &trans  &trans          &msc SCRL_UP    &trans           &trans  &trans
&trans  &trans  &mmv MOVE_LEFT  &mmv MOVE_DOWN  &mmv MOVE_RIGHT  &trans  &trans    &mkp MB3  &mkp MB3      &mkp MB3  &mkp MB3  &trans    &trans  &msc SCRL_LEFT  &msc SCRL_DOWN  &msc SCRL_RIGHT  &trans  &trans
&trans  &trans  &mkp MB4   &mkp MB5  &mkp MB3  &trans                     &trans        &mkp MB3                      &trans  &trans          &trans          &trans           &trans  &trans
&trans  &trans  &trans          &trans          &trans                   &mkp MB2  &mkp MB1  &trans        &Double_Click  &mkp MB1  &mkp MB2          &trans          &trans          &trans           &trans  &trans
            >;
        };
    };

    conditional_layers {
        compatible = "zmk,conditional-layers";

        // Activate MacOS Specific HW_Mod3 Layer (10)
        // If: Mod3 (6) && MacOS (8)

        MacOS_HW_Mod3 {
            if-layers = <6 8>;
            then-layer = <10>;
        };

        // Activate Win Specific HW_Mod3 Layer (11)
        // If: Mod3 (6) && Win (9)

        Win_HW_Mod3 {
            if-layers = <6 9>;
            then-layer = <11>;
        };
    };

    combos {
        compatible = "zmk,combos";

        // Caps Combo (Thumbs)

        combo_caps {
            timeout-ms = <50>;
            key-positions = <65 70>;
            bindings = <&prog_caps>;
        };

        // Other Combo (Thumbs)

        combo_other {
            timeout-ms = <50>;
            key-positions = <66 69>;
            bindings = <&tog 13>;
        };
    };
};
